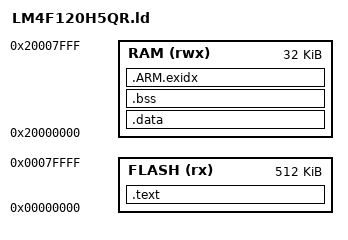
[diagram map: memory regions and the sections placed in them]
/*
 * Copyright (c) 2014 Josh Friend
 *
 * Permission is hereby granted, free of charge, to any person obtaining a copy
 * of this software and associated documentation files (the "Software"), to deal
 * in the Software without restriction, including without limitation the rights
 * to use, copy, modify, merge, publish, distribute, sublicense, and/or sell
 * copies of the Software, and to permit persons to whom the Software is
 * furnished to do so, subject to the following conditions:
 *
 * The above copyright notice and this permission notice shall be included in
 * all copies or substantial portions of the Software.
 *
 * THE SOFTWARE IS PROVIDED "AS IS", WITHOUT WARRANTY OF ANY KIND, EXPRESS OR
 * IMPLIED, INCLUDING BUT NOT LIMITED TO THE WARRANTIES OF MERCHANTABILITY,
 * FITNESS FOR A PARTICULAR PURPOSE AND NONINFRINGEMENT. IN NO EVENT SHALL THE
 * AUTHORS OR COPYRIGHT HOLDERS BE LIABLE FOR ANY CLAIM, DAMAGES OR OTHER
 * LIABILITY, WHETHER IN AN ACTION OF CONTRACT, TORT OR OTHERWISE, ARISING FROM,
 * OUT OF OR IN CONNECTION WITH THE SOFTWARE OR THE USE OR OTHER DEALINGS IN
 * THE SOFTWARE.
 */

MEMORY
{
    FLASH (rx)  : ORIGIN = 0x00000000, LENGTH = 512K
    RAM   (rwx) : ORIGIN = 0x20000000, LENGTH = 32K
}

/* The stack size should be the same size as SRAM */
STACK_SIZE = 32K;

SECTIONS
{
    /* Executable code stored in text */
    .text :
    {
        . = ALIGN(4);
        _text = .;
        KEEP(*(.isr_vector))
        *(.text .text* .gnu.linkonce.t.*)
        *(.glue_7t) *(.glue_7)
        *(.rodata .rodata* .gnu.linkonce.r.*)
        *(.ARM.extab* .gnu.linkonce.armextab.*)

        . = ALIGN(4);
        KEEP(*(.init))
        . = ALIGN(4);
        __preinit_array_start = .;
        KEEP (*(SORT(.preinit_array*)))
        KEEP (*(.preinit_array))
        __preinit_array_end = .;

        . = ALIGN(4);
        __init_array_start = .;
        KEEP (*(SORT(.init_array.*)))
        KEEP (*(.init_array))
        __init_array_end = .;

        . = ALIGN(4);
        KEEP(*(.fini))

        . = ALIGN(4);
        __fini_array_start = .;
        KEEP (*(.fini_array))
        KEEP (*(SORT(.fini_array.*)))
        __fini_array_end = .;

        . = ALIGN(4);
        _etext = .;
    } > FLASH

    .data : AT(ADDR(.text) + SIZEOF(.text))
    {
        . = ALIGN(4);
        _data = .;
        *(vtable)
        *(.data .data* .gnu.linkonce.d.*)
        _edata = .;
    } > RAM

    .bss (NOLOAD):
    {
        . = ALIGN(4);
        _bss = .;
        *(.bss .bss*)
        *(COMMON)
        . = ALIGN(4);
        _ebss = .;
        . = ALIGN(8);
    } > RAM

    PROVIDE_HIDDEN (__exidx_start = .);
    .ARM.exidx :
    {
      *(.ARM.exidx* .gnu.linkonce.armexidx.*)
    } > RAM
    PROVIDE_HIDDEN (__exidx_end = .);

    . = ALIGN(4);
    _end = . ;

}

/* end of allocated ram is start of heap, heap grows up towards stack*/
PROVIDE(end = _end);

/* top of stack starts at end of ram, stack grows down towards heap */
PROVIDE(_stack_top = ORIGIN(RAM) + LENGTH(RAM));
